AUTOSAR XML (schema 00050)
standard types defined: Boolean
package /ARRoot
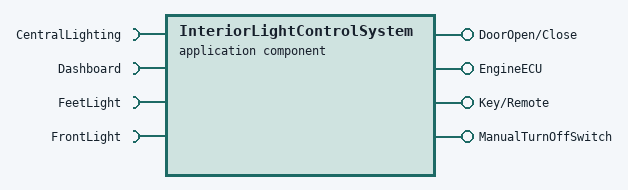
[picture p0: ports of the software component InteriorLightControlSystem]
  application sw component type InteriorLightControlSystem
    require port CentralLighting
    require port Dashboard
    provide port DoorOpen/Close
    provide port EngineECU
    require port FeetLight
    require port FrontLight
    provide port Key/Remote
    provide port ManualTurnOffSwitch
    swc-internal-behavior:
      8 x runnable, all with variable-access:
        CenteralLightingRunnable
        DashBoardRunnable
        DoorOpen/CloseRunnable
        EngineECURunnable
        FeetLightRunnable
        FrontLightRunnable
        Key/RemoteRunnable
        ManualTurnOffSwitchRunnable
    behavior InputControlIB
    behavior InteriorLightControlIB
  client server interface InteriorLightSystemCSIF: client-server-operation
  sender receiver interface InteriorLightSystemSRIF
